VERSION ""

NS_ :

BS_:

BU_:
VAL_TABLE_ Vt_EngineRunnngStatus 1 "Engine running" 0 "Engine not running" ;
VAL_TABLE_ Vt_BrakeStatus 1 "Brake applied" 0 "Brake not applied" ;

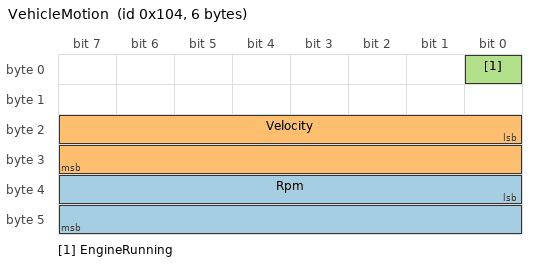
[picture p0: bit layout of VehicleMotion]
BO_ 260 VehicleMotion: 6 Vector__XXX
 SG_ Rpm : 32|16@1+ (0.1,0) [0|6553.5] "" Vector__XXX
 SG_ Velocity : 16|16@1+ (0.1,0) [0|6553.5] "km/hr" Vector__XXX
 SG_ EngineRunning : 0|1@1+ (1,0) [0|1] "Boolean" Vector__XXX

BO_ 261 BrakeMsg: 1 Vector__XXX
 SG_ BrakeStatus : 0|1@1+ (1,0) [0|1] "Boolean" Vector__XXX

BO_ 262 AccelerationMsg: 2 Vector__XXX
 SG_ Acceleration : 0|16@1+ (0.1,0) [0|65535] "m/s^2" Vector__XXX

EV_ Acceleration_Env: 0 [0|2210] "m/s^2" 0 1 DUMMY_NODE_VECTOR0 Vector__XXX;

BA_DEF_ BO_  "GenMsgCycleTime" INT 200 1000;
BA_DEF_  "BusType" STRING ;
BA_DEF_DEF_  "GenMsgCycleTime" 200;
BA_DEF_DEF_  "BusType" "CAN";
VAL_ 260 EngineRunning 1 "Engine running" 0 "Engine not running" ;
VAL_ 261 BrakeStatus 1 "Brake applied" 0 "Brake not applied" ;
